# L3INIT_PRM register map
Vendor: Texas Instruments
Peripheral module from a debugger description file (folder omap5430_ES2_PUBLIC).
Registers are 32-bit, access not given, reset 0x0 unless marked. A register's access mark holds for its fields unless they carry their own. Offsets are as the file gives them; lines under a group give offsets from that group; [hi:lo] are bit positions; {n}, {i} and the like mark numbered series; 'fields as' and 'values as' point back to an identical list; <NAME> marks a mode.

## L3INIT_PRM
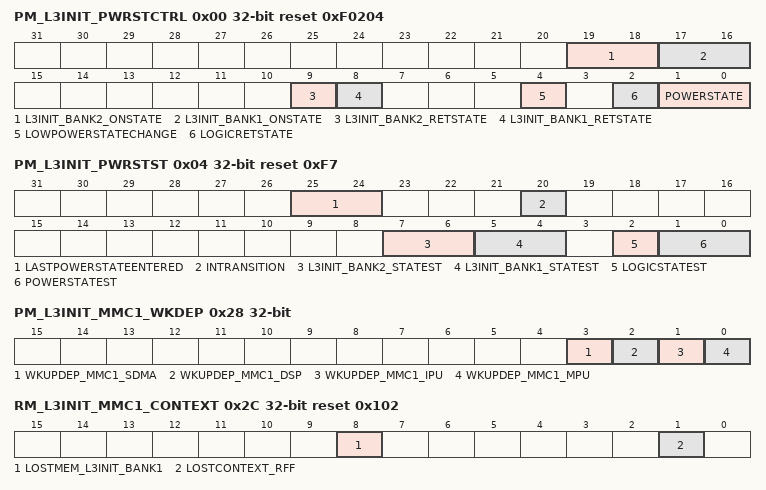
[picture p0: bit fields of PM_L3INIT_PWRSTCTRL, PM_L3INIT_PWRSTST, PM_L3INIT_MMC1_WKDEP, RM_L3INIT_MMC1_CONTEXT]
0x00 PM_L3INIT_PWRSTCTRL reset 0xF0204 — This register controls the L3INIT power state to reach upon a domain sleep transition
  [19:18] L3INIT_BANK2_ONSTATE ro — L3INIT BANK2 state when domain is ON. Read 0x3: Memory bank is on when the domain is ON.
  [17:16] L3INIT_BANK1_ONSTATE ro — L3INIT BANK1 state when domain is ON.
    3=Mem_on (Memory bank is on when the domain is ON.)
  [9] L3INIT_BANK2_RETSTATE ro — L3INIT BANK2 state when domain is RETENTION. Read 0x1: Memory bank is retained when domain is in RETENTION state.
  [8] L3INIT_BANK1_RETSTATE ro — L3INIT BANK1 state when domain is RETENTION.
    0=mem_off (Memory bank is off when the domain is in the RETENTION state.)
  [4] LOWPOWERSTATECHANGE — Power state change request when domain has already performed a sleep transition. Allows going into deeper low power state without waking up the power domain. (access RW WSpecial)
    0=DIS (Do not request a low power state change.); 1=EN (Request a low power state change. This bit is automatically cleared when the power state is effectively changed or when power state is ON.)
  [2] LOGICRETSTATE rw — Logic state when power domain is RETENTION
    0=logic_off (Only retention registers are retained and remaing logic is off when the domain is in RETENTION state.); 1=logic_ret (Whole logic is retained when domain is in RETENTION state.)
  [1:0] POWERSTATE rw — Power state control
    0=OFF (Reserved); 1=RET (RETENTION state); 2=INACT (INACTIVE state); 3=ON (ON State)
0x04 PM_L3INIT_PWRSTST reset 0xF7 — This register provides a status on the current L3INIT power domain state. [warm reset insensitive]
  [25:24] LASTPOWERSTATEENTERED — Last low power state entered. Set to 0x3 upon write of the same only. This register is intended for debug purpose only. (access RW W1toSet)
    3=ON (Power domain was previously ON-ACTIVE); 2=INACTIVE (Power domain was previously ON-INACTIVE); 1=RET (Power domain was previously in RETENTION); 0=OFF (Reserved)
  [20] INTRANSITION ro — Domain transition status
    0=No (No on-going transition on power domain); 1=Ongoing (Power domain transition is in progress.)
  [7:6] L3INIT_BANK2_STATEST ro — L3INIT BANK2 state status Read 0x0: Reserved Read 0x1: Memory is RETENTION Read 0x2: Reserved Read 0x3: Memory is ON
  [5:4] L3INIT_BANK1_STATEST ro — L3INIT BANK1 state status
    0=Mem_off (Reserved); 3=Mem_on (Memory is ON)
  [2] LOGICSTATEST ro — Logic state status
    0=OFF (Logic in domain is OFF); 1=ON (Logic in domain is ON)
  [1:0] POWERSTATEST ro — Current power state status
    0=OFF (Reserved); 1=RET (Power domain is in RETENTION); 2=INACTIVE (Power domain is ON-INACTIVE); 3=ON (Power domain is ON-ACTIVE)
0x28 PM_L3INIT_MMC1_WKDEP access per field — This register controls wakeup dependency based on MMC1 service requests.
  [all] fields
    0=Disabled (Dependency is disabled); 1=Enabled (Dependency is enabled)
  [3] WKUPDEP_MMC1_SDMA rw — Wakeup dependency from MMC1 module (SWakeup signal) towards DMA_SYSTEM + L3_MAIN2 + L4_PER clock domains
  [2] WKUPDEP_MMC1_DSP rw — Wakeup dependency from MMC1 module (SWakeup signal) towards DSP + L3_MAIN1 + L3_MAIN2 + L4_PER clock domains
  [1] WKUPDEP_MMC1_IPU rw — Wakeup dependency from MMC1 module (SWakeup signal) towards IPU + L3_MAIN2 + L4_PER clock domains
  [0] WKUPDEP_MMC1_MPU rw — Wakeup dependency from MMC1 module (SWakeup signal) towards MPU + L3_MAIN1 + L3_MAIN2 + L4_PER clock domains
0x2C RM_L3INIT_MMC1_CONTEXT reset 0x102 — This register contains dedicated MMC1 context statuses. [warm reset insensitive]
  [8] LOSTMEM_L3INIT_BANK1 — Specify if memory-based context in L3INIT_BANK1 memory bank has been lost due to a previous power transition or other reset source. (access RW W1toClr)
    0=Maintained (Context has been maintained); 1=Lost (Context has been lost)
  [1] LOSTCONTEXT_RFF — Specify if RFF-based context has been lost due to a previous power transition or other reset source. (set upon assertion of L3INIT_RET_RST signal) (access RW W1toClr)
    values as LOSTMEM_L3INIT_BANK1
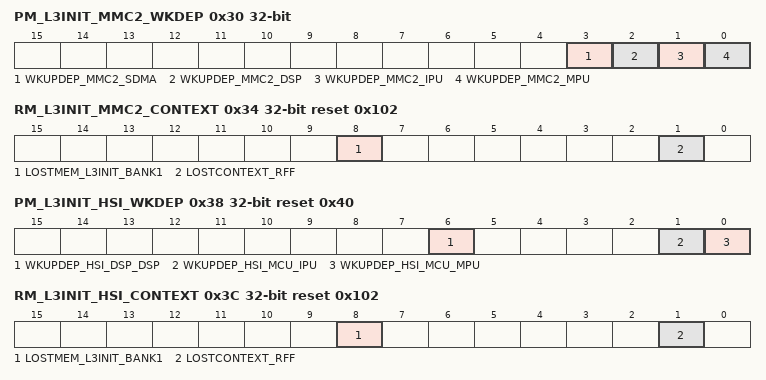
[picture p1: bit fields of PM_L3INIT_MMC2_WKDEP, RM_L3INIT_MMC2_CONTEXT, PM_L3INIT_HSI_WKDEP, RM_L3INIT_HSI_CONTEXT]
0x30 PM_L3INIT_MMC2_WKDEP access per field — This register controls wakeup dependency based on MMC2 service requests.
  [all] fields
    values as the fields of PM_L3INIT_MMC1_WKDEP
  [3] WKUPDEP_MMC2_SDMA rw — Wakeup dependency from MMC2 module (SWakeup signal) towards DMA_SYSTEM + L3_MAIN2 + L4_PER clock domains
  [2] WKUPDEP_MMC2_DSP rw — Wakeup dependency from MMC2 module (SWakeup signal) towards DSP + L3_MAIN1 + L3_MAIN2 + L4_PER clock domains
  [1] WKUPDEP_MMC2_IPU rw — Wakeup dependency from MMC2 module (SWakeup signal) towards IPU + L3_MAIN2 + L4_PER clock domains
  [0] WKUPDEP_MMC2_MPU rw — Wakeup dependency from MMC2 module (SWakeup signal) towards MPU + L3_MAIN1 + L3_MAIN2 + L4_PER clock domains
0x34 RM_L3INIT_MMC2_CONTEXT reset 0x102 — This register contains dedicated MMC2 context statuses. [warm reset insensitive]
  fields as RM_L3INIT_MMC1_CONTEXT
0x38 PM_L3INIT_HSI_WKDEP access per field reset 0x40 — This register controls wakeup dependency based on HSI service requests.
  [all] fields
    values as the fields of PM_L3INIT_MMC1_WKDEP
  [6] WKUPDEP_HSI_DSP_DSP rw — Wakeup dependency from HSI module (SWakeup_DSP signal) towards DSP + L3MAIN1 + L4CFG domains
  [1] WKUPDEP_HSI_MCU_IPU rw — Wakeup dependency from HSI module (SWakeup_MPU signal) towards IPU + L3MAIN2 + L3MAIN1 + L4CFG domains
  [0] WKUPDEP_HSI_MCU_MPU rw — Wakeup dependency from HSI module (SWakeup_MPU signal) towards MPU + L3MAIN1 + L4CFG domains
0x3C RM_L3INIT_HSI_CONTEXT reset 0x102 — This register contains dedicated HSI context statuses. [warm reset insensitive]
  fields as RM_L3INIT_MMC1_CONTEXT
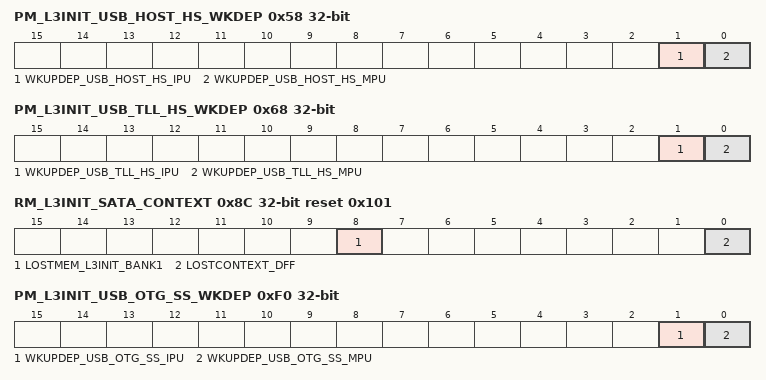
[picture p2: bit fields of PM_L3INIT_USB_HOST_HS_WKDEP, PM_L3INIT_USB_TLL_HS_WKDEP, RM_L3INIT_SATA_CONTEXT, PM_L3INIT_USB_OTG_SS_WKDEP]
0x58 PM_L3INIT_USB_HOST_HS_WKDEP access per field — This register controls wakeup dependency based on USB_HOST_HS service requests.
  [1] WKUPDEP_USB_HOST_HS_IPU rw — Wakeup dependency from USB_HOST_HS module (SWakeup signal) towards IPU + L3_MAIN2 + L3_MAIN1 + L4_CFG domains
    values as the fields of PM_L3INIT_MMC1_WKDEP
  [0] WKUPDEP_USB_HOST_HS_MPU rw — Wakeup dependency from USB_HOST_HS module (SWakeup signal) towards MPU + L3_MAIN1 + L4_CFG domains
    values as the fields of PM_L3INIT_MMC1_WKDEP
0x5C RM_L3INIT_USB_HOST_HS_CONTEXT reset 0x2 — This register contains dedicated USB_HOST_HS context statuses. [warm reset insensitive]
  [1] LOSTCONTEXT_RFF — Specify if RFF-based context has been lost due to a previous power transition or other reset source. (set upon assertion of L3INIT_RET_RST signal) (access RW W1toClr)
    values as RM_L3INIT_MMC1_CONTEXT.LOSTMEM_L3INIT_BANK1
0x68 PM_L3INIT_USB_TLL_HS_WKDEP access per field — This register controls wakeup dependency based on USB_TLL_HS service requests.
  [1] WKUPDEP_USB_TLL_HS_IPU rw — Wakeup dependency from USB_TLL_HS module (SWakeup signal) towards IPU + L3_MAIN2 + L3_MAIN1 + L4_CFG domains
    values as the fields of PM_L3INIT_MMC1_WKDEP
  [0] WKUPDEP_USB_TLL_HS_MPU rw — Wakeup dependency from USB_TLL_HS module (SWakeup signal) towards MPU + L3_MAIN1 + L4_CFG domains
    values as the fields of PM_L3INIT_MMC1_WKDEP
0x6C RM_L3INIT_USB_TLL_HS_CONTEXT reset 0x2 — This register contains dedicated USB_TLL_HS context statuses. [warm reset insensitive]
  fields as RM_L3INIT_USB_HOST_HS_CONTEXT
0x7C RM_L3INIT_IEEE1500_2_OCP_CONTEXT reset 0x1 — This register contains dedicated IEEE1500_2_OCP context statuses. [warm reset insensitive]
  [0] LOSTCONTEXT_DFF — Specify if DFF-based context has been lost due to a previous power transition or other reset source. (set upon assertion of L3INIT_RST signal) (access RW W1toClr)
    values as RM_L3INIT_MMC1_CONTEXT.LOSTMEM_L3INIT_BANK1
0x88 PM_L3INIT_SATA_WKDEP access per field — This register controls wakeup dependency based on SATA service requests.
  [0] WKUPDEP_SATA_MPU rw — Wakeup dependency from SATA module (SWakeup signal) towards MPU + L3MAIN1 + L4CFG domains
    values as the fields of PM_L3INIT_MMC1_WKDEP
0x8C RM_L3INIT_SATA_CONTEXT reset 0x101 — This register contains dedicated SATA context statuses. [warm reset insensitive]
  [8] LOSTMEM_L3INIT_BANK1 — Specify if memory-based context in L3INIT_BANK1 memory bank has been lost due to a previous power transition or other reset source. (access RW W1toClr)
    values as RM_L3INIT_MMC1_CONTEXT.LOSTMEM_L3INIT_BANK1
  [0] LOSTCONTEXT_DFF — Specify if DFF-based context has been lost due to a previous power transition or other reset source. (set upon assertion of L3INIT_RST signal) (access RW W1toClr)
    values as RM_L3INIT_MMC1_CONTEXT.LOSTMEM_L3INIT_BANK1
0xE4 RM_L3INIT_OCP2SCP1_CONTEXT reset 0x1 — This register contains dedicated OCP2SCP1 context statuses. [warm reset insensitive]
  fields as RM_L3INIT_IEEE1500_2_OCP_CONTEXT
0xEC RM_L3INIT_OCP2SCP3_CONTEXT reset 0x1 — This register contains dedicated OCP2SCP3 context statuses. [warm reset insensitive]
  fields as RM_L3INIT_IEEE1500_2_OCP_CONTEXT
0xF0 PM_L3INIT_USB_OTG_SS_WKDEP access per field — This register controls wakeup dependency based on USB_OTG_SS service requests.
  [1] WKUPDEP_USB_OTG_SS_IPU rw — Wakeup dependency from USB_OTG_SS module (SWakeup signal) towards IPU + L3_MAIN2 + L3_MAIN1 + L4_CFG domains
    values as the fields of PM_L3INIT_MMC1_WKDEP
  [0] WKUPDEP_USB_OTG_SS_MPU rw — Wakeup dependency from USB_OTG_SS module (SWakeup signal) towards MPU + L3_MAIN1 + L4_CFG domains
    values as the fields of PM_L3INIT_MMC1_WKDEP
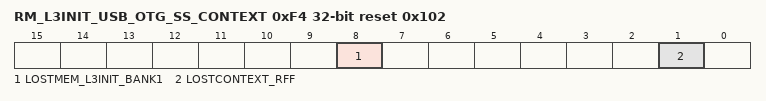
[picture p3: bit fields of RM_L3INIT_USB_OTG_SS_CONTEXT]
0xF4 RM_L3INIT_USB_OTG_SS_CONTEXT reset 0x102 — This register contains dedicated USB_OTG_SS context statuses. [warm reset insensitive]
  fields as RM_L3INIT_MMC1_CONTEXT
